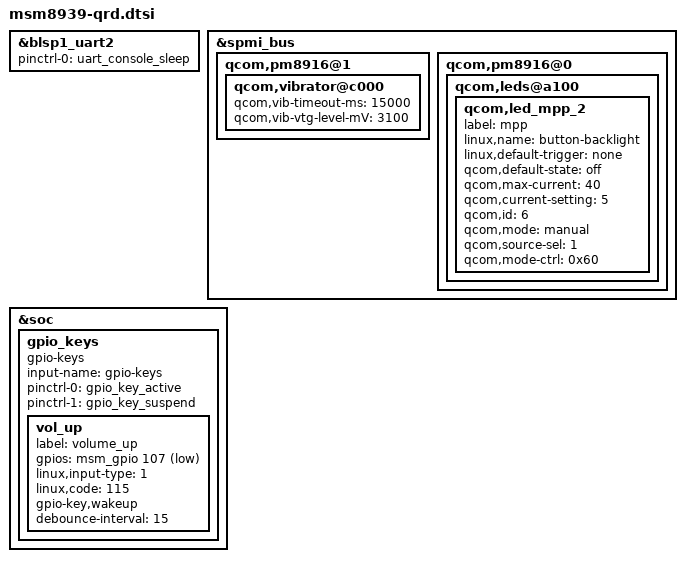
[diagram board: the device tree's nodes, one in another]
/* Copyright (c) 2014, The Linux Foundation. All rights reserved.
 *
 * This program is free software; you can redistribute it and/or modify
 * it under the terms of the GNU General Public License version 2 and
 * only version 2 as published by the Free Software Foundation.
 *
 * This program is distributed in the hope that it will be useful,
 * but WITHOUT ANY WARRANTY; without even the implied warranty of
 * MERCHANTABILITY or FITNESS FOR A PARTICULAR PURPOSE.  See the
 * GNU General Public License for more details.
 */

#include "msm8939.dtsi"
#include "msm8939-pinctrl.dtsi"

&blsp1_uart2 {
	status = "ok";
	pinctrl-names = "default";
	pinctrl-0 = <&uart_console_sleep>;
};

&spmi_bus {
	qcom,pm8916@1 {
		qcom,vibrator@c000 {
			status = "okay";
			qcom,vib-timeout-ms = <15000>;
			qcom,vib-vtg-level-mV = <3100>;
		};
	};

	qcom,pm8916@0 {
		qcom,leds@a100 {
			status = "okay";
			qcom,led_mpp_2 {
				label = "mpp";
				linux,name = "button-backlight";
				linux,default-trigger = "none";
				qcom,default-state = "off";
				qcom,max-current = <40>;
				qcom,current-setting = <5>;
				qcom,id = <6>;
				qcom,mode = "manual";
				qcom,source-sel = <1>;
				qcom,mode-ctrl = <0x60>;
			};
		};
	};
};

&soc {
	gpio_keys {
		compatible = "gpio-keys";
		input-name = "gpio-keys";
		pinctrl-names = "tlmm_gpio_key_active","tlmm_gpio_key_suspend";
		pinctrl-0 = <&gpio_key_active>;
		pinctrl-1 = <&gpio_key_suspend>;

		vol_up {
			label = "volume_up";
			gpios = <&msm_gpio 107 0x1>;
			linux,input-type = <1>;
			linux,code = <115>;
			gpio-key,wakeup;
			debounce-interval = <15>;
		};
	};
};
